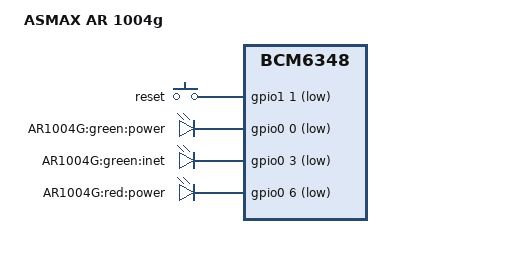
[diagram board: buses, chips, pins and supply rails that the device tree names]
/dts-v1/;

#include "bcm6348.dtsi"

#include <dt-bindings/input/input.h>

/ {
	model = "ASMAX AR 1004g";
	compatible = "asmax,ar1004g", "brcm,bcm6348";

	gpio-keys-polled {
		compatible = "gpio-keys-polled";
		#address-cells = <1>;
		#size-cells = <0>;
		poll-interval = <20>;
		debounce-interval = <60>;

		reset {
			label = "reset";
			gpios = <&gpio1 1 1>;
			linux,code = <KEY_RESTART>;
		};
	};

	gpio-leds {
		compatible = "gpio-leds";

		power_green {
			label = "AR1004G:green:power";
			gpios = <&gpio0 0 1>;
			default-state = "on";
		};
		inet_green {
			label = "AR1004G:green:inet";
			gpios = <&gpio0 3 1>;
		};
		power_red {
			label = "AR1004G:red:power";
			gpios = <&gpio0 6 1>;
		};
	};
};
